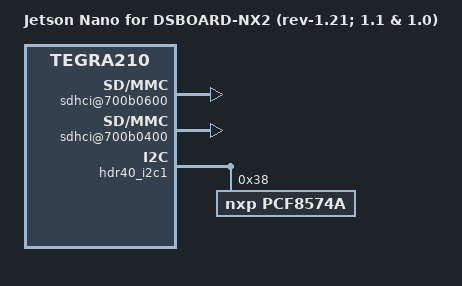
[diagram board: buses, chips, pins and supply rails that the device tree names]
/*
 * arch/arm64/boot/dts/tegra210-p3448-0002-p3449-0000-b00.dts
 *
 * Copyright (c) 2018-2021, NVIDIA CORPORATION.  All rights reserved.
 *
 * This program is free software; you can redistribute it and/or modify
 * it under the terms of the GNU General Public License as published by
 * the Free Software Foundation; version 2 of the License.
 *
 * This program is distributed in the hope that it will be useful, but WITHOUT
 * ANY WARRANTY; without even the implied warranty of MERCHANTABILITY or
 * FITNESS FOR A PARTICULAR PURPOSE.  See the GNU General Public License for
 * more details.
 *
 * You should have received a copy of the GNU General Public License along
 * with this program; if not, write to the Free Software Foundation, Inc.,
 * 51 Franklin Street, Fifth Floor, Boston, MA  02110-1301, USA.
 *
 */

#include "tegra210-porg-p3448-common.dtsi"
#include "porg-platforms/tegra210-porg-camera-rbpcv3-dual-imx477.dtsi"
#include "porg-platforms/tegra210-porg-camera-rbpcv2-dual-imx219.dtsi"
#include "porg-platforms/tegra210-porg-pinmux-p3448-0002-b00.dtsi"
#include "porg-platforms/tegra210-porg-gpio-p3448-0002-b00.dtsi"
#include "porg-platforms/tegra210-porg-p3448-emc-a00.dtsi"
#include "tegra210-disable-debug-rx.dtsi"
#include "tegra210-enable-spi.dtsi"

#define FORECR_CAM_I2C_MUX TEGRA_GPIO(Z, 0) // GPIO11

/ {
	model = "Jetson Nano for DSBOARD-NX2 (rev-1.21; 1.1 & 1.0)";
	compatible ="nvidia,p3449-0000-b00+p3448-0002-b00", "nvidia,jetson-nano", "nvidia,tegra210";
	nvidia,dtsfilename = __FILE__;

	sdhci@700b0600 { /* SDMMC4 for EMMC */
		status = "okay";
	};

	sdhci@700b0400 {
		status = "okay";
		/delete-property/ keep-power-in-suspend;
		/delete-property/ non-removable;
		nvidia,vmmc-always-on;
	};

	sdhci@700b0000 { /* SDMMC1 for SD card */
		status = "disabled";
	};

	spi@70410000 { /* QSPI */
		status = "disabled";
	};

	pwm-fan {
		status = "disabled";
	};
	
	hdr40_i2c1: i2c@7000c400 {
		pcf8574a: gpio@38 {
			compatible = "nxp,pcf8574a";
			reg = <0x38>;
			gpio-controller;
			#gpio-cells = <2>;
		};

	};

	cam_i2cmux {
		mux-gpios = <&gpio FORECR_CAM_I2C_MUX GPIO_ACTIVE_HIGH>;
	};

	gpio@6000d000 {
			/* gpio-name for 40-pin header, gpio-name given as COL(10) x ROW(20) */
			gpio-line-names = "",   "",     "",     "",     "",     "",     "",     "",     "",     "",
			"",     "",     "SPI1_MOSI",    "SPI1_MISO",    "SPI1_SCK",     "SPI1_CS0",     "SPI0_MOSI",    "SPI0_MISO",    "SPI0_SCK",     "SPI0_CS0",
			"SPI0_CS1",     "",     "",     "",     "",     "",     "",     "",     "",     "",
			"",     "",     "",     "",     "",     "",     "",     "",     "GPIO13",      "",
			"",     "",     "",     "",     "",     "",     "",     "",     "",     "",
			"UART1_RTS",    "UART1_CTS",    "",     "",     "",     "",     "",     "",     "",     "",
			"",     "",     "",     "",     "",     "",     "",     "",     "",     "",
			"",     "",     "",     "",     "",     "",     "I2S0_FS",    "I2S0_DIN",    "I2S0_DOUT",   "I2S0_SCLK",
			"",     "",     "",     "",     "",     "",     "",     "",     "",     "",
			"",     "",     "",     "",     "",     "",     "",     "",     "",     "",
			"",     "",     "",     "",     "",     "",     "",     "",     "",     "",
			"",     "",     "",     "",     "",     "",     "",     "",     "",     "",
			"",     "",     "",     "",     "",     "",     "",     "",     "",     "",
			"",     "",     "",     "",     "",     "",     "",     "",     "",     "",
			"",     "",     "",     "",     "",     "",     "",     "",     "",     "GPIO01",
			"",     "",     "",     "",     "",     "",     "",     "",     "",     "",
			"",     "",     "",     "",     "",     "",     "",     "",     "GPIO07",   "",
			"",     "",     "",     "",     "",     "",     "",     "",     "",     "",
			"",     "",     "",     "",     "",     "",     "",     "",     "",     "",
			"",     "",     "",     "",     "GPIO12",       "",     "",     "",     "",     "",
			"GPIO11",      "",     "",     "",     "",     "",     "",     "",     "",     "",
			"",     "",     "",     "",     "",     "",     "GPIO09",     "",     "",     "",
			"",     "",     "",     "",     "",     "",     "",     "",     "",     "",
			"",     "",     "SPI1_CS1",     "",     "",     "",     "",     "",     "",     "";
	};
};
